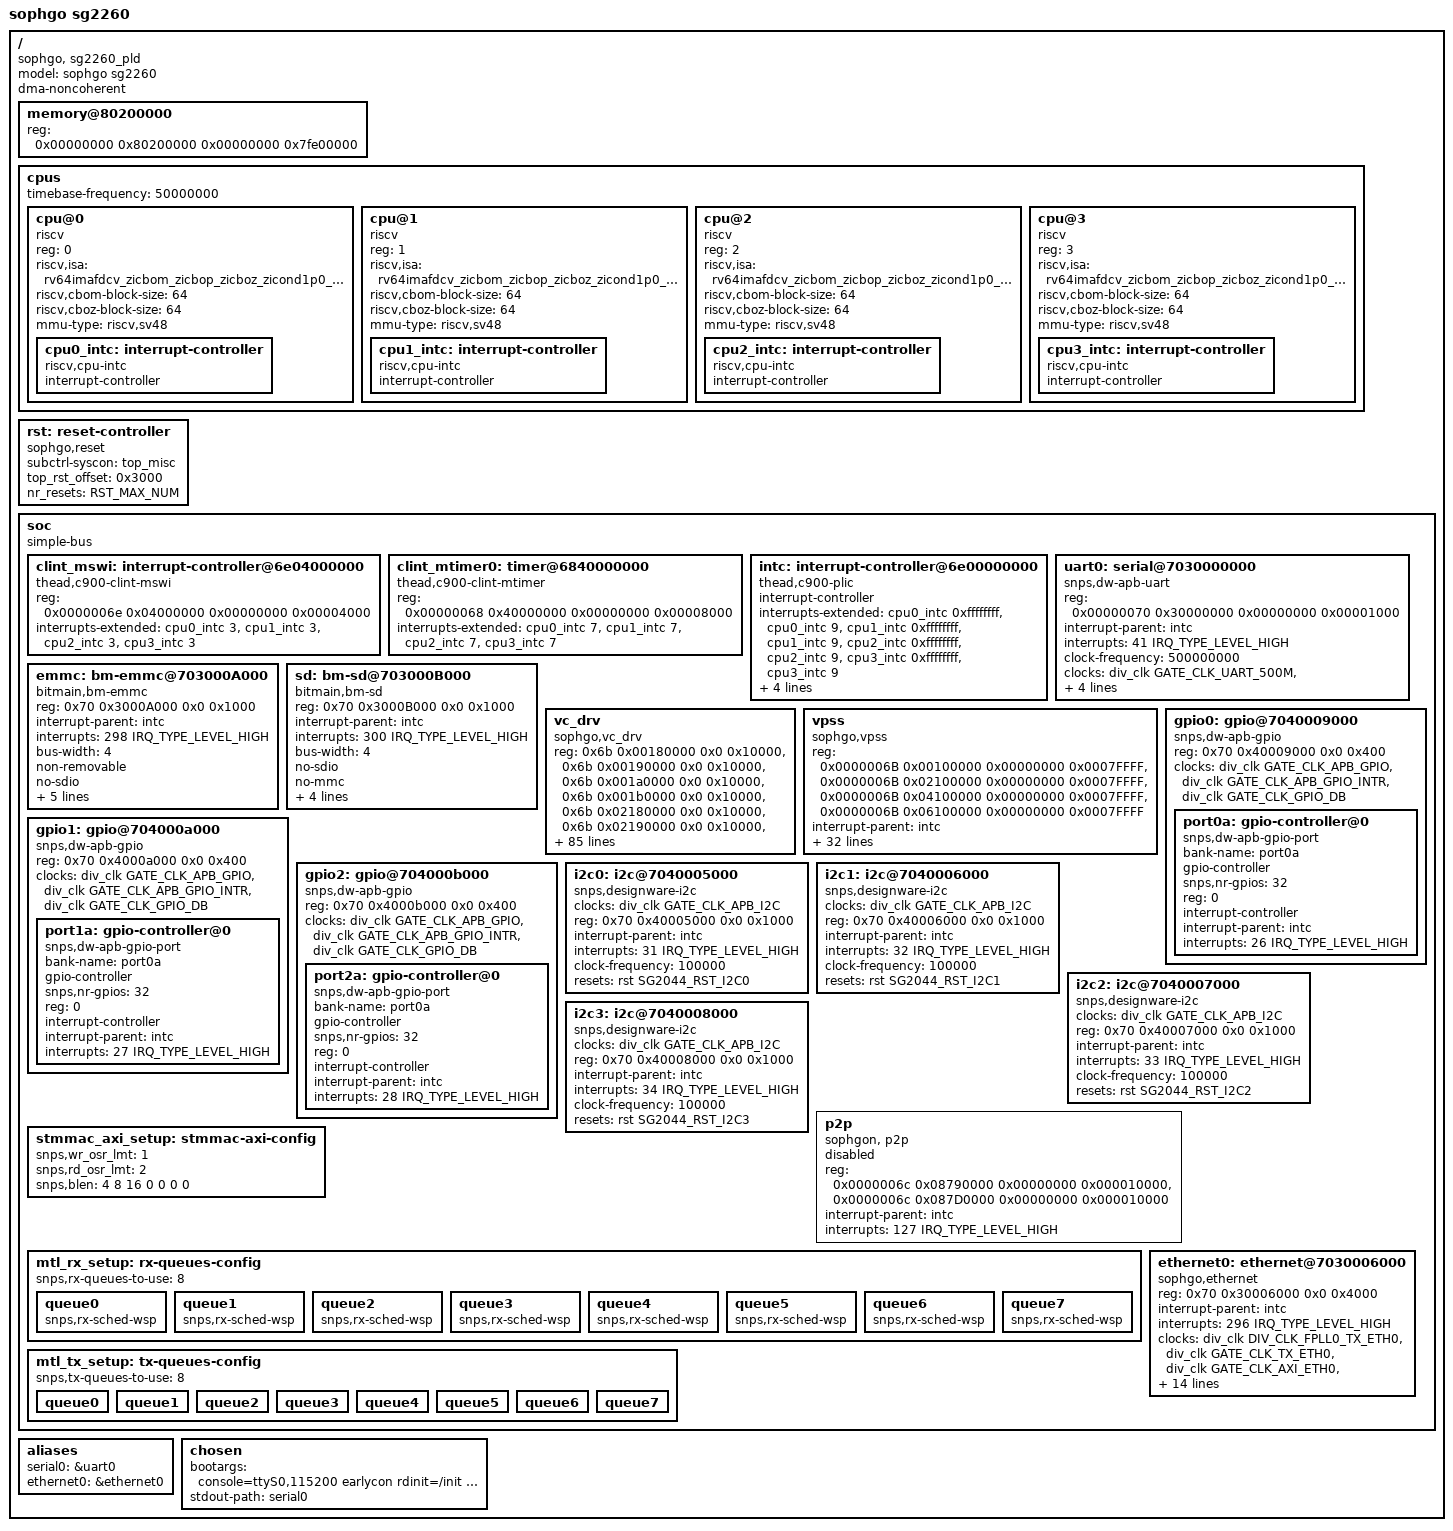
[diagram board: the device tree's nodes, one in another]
// SPDX-License-Identifier: (GPL-2.0 OR MIT)
/*
 * Copyright (C) 2022 Sophgo Technology Inc. All rights reserved.
 */

/dts-v1/;
#include <dt-bindings/interrupt-controller/irq.h>
#include <dt-bindings/reset/sophgo,sg2044-reset.h>
#include <dt-bindings/clock/sophgo,sg2044-clock.h>
#include "sg2044-clock.dtsi"
#include "sg2044-pinctrl.dtsi"

/ {
	model = "sophgo sg2260";
	compatible = "sophgo, sg2260_pld";
	#address-cells = <2>;
	#size-cells = <2>;
	dma-noncoherent;

	memory@80200000 {
		device_type = "memory";
		reg = <0x00000000 0x80200000 0x00000000 0x7fe00000>;
	};

	cpus {
		#address-cells = <1>;
		#size-cells = <0>;
		timebase-frequency = <50000000>;
		cpu@0 {
			device_type = "cpu";
			reg = <0>;
			status = "okay";
			compatible = "riscv";
			riscv,isa = "rv64imafdcv_zicbom_zicbop_zicboz_zicond1p0_zihintntl0p2_zihintpause_zawrs_zfa0p1_zfbfmin0p8_zfh_zca_zcb_zcd_zba_zbb_zbc_zbs_zvfbfmin0p8_zvfbfwma0p8_zvfh0p1_sscofpmf_sstc_svinval_svnapot_svpbmt";
			riscv,cbom-block-size = <64>;
			riscv,cboz-block-size = <64>;
			mmu-type = "riscv,sv48";
			cpu0_intc: interrupt-controller {
				#interrupt-cells = <1>;
				compatible = "riscv,cpu-intc";
				interrupt-controller;
			};
		};
		cpu@1 {
			device_type = "cpu";
			reg = <1>;
			status = "okay";
			compatible = "riscv";
			riscv,isa = "rv64imafdcv_zicbom_zicbop_zicboz_zicond1p0_zihintntl0p2_zihintpause_zawrs_zfa0p1_zfbfmin0p8_zfh_zca_zcb_zcd_zba_zbb_zbc_zbs_zvfbfmin0p8_zvfbfwma0p8_zvfh0p1_sscofpmf_sstc_svinval_svnapot_svpbmt";
			riscv,cbom-block-size = <64>;
			riscv,cboz-block-size = <64>;
			mmu-type = "riscv,sv48";
			cpu1_intc: interrupt-controller {
				#interrupt-cells = <1>;
				compatible = "riscv,cpu-intc";
				interrupt-controller;
			};
		};
		cpu@2 {
			device_type = "cpu";
			reg = <2>;
			status = "okay";
			compatible = "riscv";
			riscv,isa = "rv64imafdcv_zicbom_zicbop_zicboz_zicond1p0_zihintntl0p2_zihintpause_zawrs_zfa0p1_zfbfmin0p8_zfh_zca_zcb_zcd_zba_zbb_zbc_zbs_zvfbfmin0p8_zvfbfwma0p8_zvfh0p1_sscofpmf_sstc_svinval_svnapot_svpbmt";
			riscv,cbom-block-size = <64>;
			riscv,cboz-block-size = <64>;
			mmu-type = "riscv,sv48";
			cpu2_intc: interrupt-controller {
				#interrupt-cells = <1>;
				compatible = "riscv,cpu-intc";
				interrupt-controller;
			};
		};
		cpu@3 {
			device_type = "cpu";
			reg = <3>;
			status = "okay";
			compatible = "riscv";
			riscv,isa = "rv64imafdcv_zicbom_zicbop_zicboz_zicond1p0_zihintntl0p2_zihintpause_zawrs_zfa0p1_zfbfmin0p8_zfh_zca_zcb_zcd_zba_zbb_zbc_zbs_zvfbfmin0p8_zvfbfwma0p8_zvfh0p1_sscofpmf_sstc_svinval_svnapot_svpbmt";
			riscv,cbom-block-size = <64>;
			riscv,cboz-block-size = <64>;
			mmu-type = "riscv,sv48";
			cpu3_intc: interrupt-controller {
				#interrupt-cells = <1>;
				compatible = "riscv,cpu-intc";
				interrupt-controller;
			};
		};
	};

	rst: reset-controller {
		#reset-cells = <1>;
		compatible = "sophgo,reset";
		subctrl-syscon = <&top_misc>;
		top_rst_offset = <0x3000>;
		nr_resets = <RST_MAX_NUM>;
	};

	soc {
		#address-cells = <2>;
		#size-cells = <2>;
		compatible = "simple-bus";
		ranges;

		clint_mswi: interrupt-controller@6e04000000 {
			compatible = "thead,c900-clint-mswi";
			reg = <0x0000006e 0x04000000 0x00000000 0x00004000>;
			interrupts-extended = <
				&cpu0_intc 3
				&cpu1_intc 3
				&cpu2_intc 3
				&cpu3_intc 3
				>;
		};

		clint_mtimer0: timer@6840000000 {
			compatible = "thead,c900-clint-mtimer";
			reg = <0x00000068 0x40000000 0x00000000 0x00008000>;
			interrupts-extended = <
				&cpu0_intc 7
				&cpu1_intc 7
				&cpu2_intc 7
				&cpu3_intc 7
				>;
		};

		//4cores PLIC2
		intc: interrupt-controller@6e00000000 {
			compatible = "thead,c900-plic";
			#address-cells = <0>;
			#interrupt-cells = <2>;
			interrupt-controller;
			interrupts-extended = <
				&cpu0_intc  0xffffffff &cpu0_intc  9
				&cpu1_intc  0xffffffff &cpu1_intc  9
				&cpu2_intc  0xffffffff &cpu2_intc  9
				&cpu3_intc  0xffffffff &cpu3_intc  9
				>;
			reg = <0x0000006e 0x00000000 0x00000000 0x10000000>;
			reg-names = "control";
			riscv,max-priority = <7>;
			riscv,ndev = <415>;
		};

		uart0: serial@7030000000 {
			compatible = "snps,dw-apb-uart";
			reg = <0x00000070 0x30000000 0x00000000 0x00001000>;
			interrupt-parent = <&intc>;
			interrupts = <41 IRQ_TYPE_LEVEL_HIGH>;
			clock-frequency = <500000000>;
			clocks = <&div_clk GATE_CLK_UART_500M>,
					 <&div_clk GATE_CLK_APB_UART>;
			clock-names = "baudclk", "apb_pclk";
			current-speed = <115200>;
			reg-shift = <2>;
			reg-io-width = <4>;
		};

		emmc: bm-emmc@703000A000 {
			compatible = "bitmain,bm-emmc";
			reg = <0x70 0x3000A000 0x0 0x1000>;
			reg-names = "core_mem";
			interrupt-parent = <&intc>;
			interrupts = <298 IRQ_TYPE_LEVEL_HIGH>;
			bus-width = <4>;
			non-removable;
			no-sdio;
			no-sd;
			resets = <&rst SG2044_RST_EMMC>;
			reset-names = "emmc";
			clocks =
				<&div_clk GATE_CLK_EMMC>,
				<&div_clk GATE_CLK_AXI_EMMC>,
				<&div_clk GATE_CLK_100K_EMMC>;
			clock-names =
				"clk_gate_emmc",
				"clk_gate_axi_emmc",
				"clk_gate_100k_emmc";
		};

		sd: bm-sd@703000B000 {
			compatible = "bitmain,bm-sd";
			reg = <0x70 0x3000B000 0x0 0x1000>;
			reg-names = "core_mem";
			interrupt-parent = <&intc>;
			interrupts = <300 IRQ_TYPE_LEVEL_HIGH>;
			bus-width = <4>;
			no-sdio;
			no-mmc;
			resets = <&rst SG2044_RST_SD>;
			reset-names = "sdio";
			clocks =
				<&div_clk GATE_CLK_SD>,
				<&div_clk GATE_CLK_AXI_SD>,
				<&div_clk GATE_CLK_100K_SD>;
			clock-names =
				"clk_gate_sd",
				"clk_gate_axi_sd",
				"clk_gate_100k_sd";
		};

		// video & jpeg
		vc_drv {
            #interrupt-cells = <1>;
            compatible = "sophgo,vc_drv";
            reg = <0x6b 0x00180000 0x0 0x10000>, <0x6b 0x00190000 0x0 0x10000>,
                <0x6b 0x001a0000 0x0 0x10000>, <0x6b 0x001b0000 0x0 0x10000>,
                <0x6b 0x02180000 0x0 0x10000>, <0x6b 0x02190000 0x0 0x10000>,
                <0x6b 0x021a0000 0x0 0x10000>, <0x6b 0x021b0000 0x0 0x10000>,
                <0x6b 0x04180000 0x0 0x10000>, <0x6b 0x04190000 0x0 0x10000>,
                <0x6b 0x041a0000 0x0 0x10000>, <0x6b 0x041b0000 0x0 0x10000>,
                <0x6b 0x06180000 0x0 0x10000>, <0x6b 0x06190000 0x0 0x10000>,
                <0x6b 0x061a0000 0x0 0x10000>, <0x6b 0x061b0000 0x0 0x10000>,
                <0x00 0x00010000 0x0 0x10000>, <0x00 0x00020000 0x0 0x10000>,
                <0x00 0x02010000 0x0 0x10000>, <0x00 0x02020000 0x0 0x10000>,
                <0x00 0x04010000 0x0 0x10000>, <0x00 0x04020000 0x0 0x10000>,
                <0x00 0x06010000 0x0 0x10000>, <0x00 0x06020000 0x0 0x10000>,
                <0x6b 0x00040000 0x0 0x10000>, <0x6b 0x00042000 0x0 0x10000>,
                <0x6b 0x02040000 0x0 0x10000>, <0x6b 0x02042000 0x0 0x10000>,
                <0x6b 0x04040000 0x0 0x10000>, <0x6b 0x04042000 0x0 0x10000>,
                <0x6b 0x06040000 0x0 0x10000>, <0x6b 0x06042000 0x0 0x10000>;

            clocks = <&div_clk GATE_CLK_SRC0>,
                <&div_clk GATE_CLK_SRC1>;
            clock-names = "vc_clk_src0", "vc_intr_src1";

            interrupt-parent = <&intc>;
            interrupts =<161 IRQ_TYPE_LEVEL_HIGH>, <162 IRQ_TYPE_LEVEL_HIGH>,
                    <167 IRQ_TYPE_LEVEL_HIGH>, <168 IRQ_TYPE_LEVEL_HIGH>,
                    <201 IRQ_TYPE_LEVEL_HIGH>, <202 IRQ_TYPE_LEVEL_HIGH>,
                    <207 IRQ_TYPE_LEVEL_HIGH>, <208 IRQ_TYPE_LEVEL_HIGH>,
                    <241 IRQ_TYPE_LEVEL_HIGH>, <242 IRQ_TYPE_LEVEL_HIGH>,
                    <247 IRQ_TYPE_LEVEL_HIGH>, <248 IRQ_TYPE_LEVEL_HIGH>,
                    <281 IRQ_TYPE_LEVEL_HIGH>, <282 IRQ_TYPE_LEVEL_HIGH>,
                    <287 IRQ_TYPE_LEVEL_HIGH>, <288 IRQ_TYPE_LEVEL_HIGH>,
                    <136 IRQ_TYPE_LEVEL_HIGH>, <140 IRQ_TYPE_LEVEL_HIGH>,
                    <176 IRQ_TYPE_LEVEL_HIGH>, <180 IRQ_TYPE_LEVEL_HIGH>,
                    <216 IRQ_TYPE_LEVEL_HIGH>, <220 IRQ_TYPE_LEVEL_HIGH>,
                    <256 IRQ_TYPE_LEVEL_HIGH>, <260 IRQ_TYPE_LEVEL_HIGH>,
                    <137 IRQ_TYPE_LEVEL_HIGH>, <141 IRQ_TYPE_LEVEL_HIGH>,
                    <177 IRQ_TYPE_LEVEL_HIGH>, <181 IRQ_TYPE_LEVEL_HIGH>,
                    <217 IRQ_TYPE_LEVEL_HIGH>, <221 IRQ_TYPE_LEVEL_HIGH>,
                    <257 IRQ_TYPE_LEVEL_HIGH>, <261 IRQ_TYPE_LEVEL_HIGH>,
                    <138 IRQ_TYPE_LEVEL_HIGH>, <142 IRQ_TYPE_LEVEL_HIGH>,
                    <178 IRQ_TYPE_LEVEL_HIGH>, <182 IRQ_TYPE_LEVEL_HIGH>,
                    <218 IRQ_TYPE_LEVEL_HIGH>, <222 IRQ_TYPE_LEVEL_HIGH>,
                    <258 IRQ_TYPE_LEVEL_HIGH>, <262 IRQ_TYPE_LEVEL_HIGH>,
                    <139 IRQ_TYPE_LEVEL_HIGH>, <143 IRQ_TYPE_LEVEL_HIGH>,
                    <179 IRQ_TYPE_LEVEL_HIGH>, <183 IRQ_TYPE_LEVEL_HIGH>,
                    <219 IRQ_TYPE_LEVEL_HIGH>, <223 IRQ_TYPE_LEVEL_HIGH>,
                    <259 IRQ_TYPE_LEVEL_HIGH>, <263 IRQ_TYPE_LEVEL_HIGH>,
                    <148 IRQ_TYPE_LEVEL_HIGH>, <149 IRQ_TYPE_LEVEL_HIGH>,
                    <188 IRQ_TYPE_LEVEL_HIGH>, <189 IRQ_TYPE_LEVEL_HIGH>,
                    <228 IRQ_TYPE_LEVEL_HIGH>, <229 IRQ_TYPE_LEVEL_HIGH>,
                    <267 IRQ_TYPE_LEVEL_HIGH>, <268 IRQ_TYPE_LEVEL_HIGH>;
		};

		vpss {
            #interrupt-cells = <1>;
            compatible = "sophgo,vpss";
            reg = <0x0000006B 0x00100000 0x00000000 0x0007FFFF>,
                <0x0000006B 0x02100000 0x00000000 0x0007FFFF>,
                <0x0000006B 0x04100000 0x00000000 0x0007FFFF>,
                <0x0000006B 0x06100000 0x00000000 0x0007FFFF>;

            interrupt-parent = <&intc>;
            interrupts = <157 IRQ_TYPE_LEVEL_HIGH>, <158 IRQ_TYPE_LEVEL_HIGH>,
                    <159 IRQ_TYPE_LEVEL_HIGH>, <160 IRQ_TYPE_LEVEL_HIGH>,
                    <163 IRQ_TYPE_LEVEL_HIGH>, <164 IRQ_TYPE_LEVEL_HIGH>,
                    <165 IRQ_TYPE_LEVEL_HIGH>, <166 IRQ_TYPE_LEVEL_HIGH>,
                    <197 IRQ_TYPE_LEVEL_HIGH>, <198 IRQ_TYPE_LEVEL_HIGH>,
                    <199 IRQ_TYPE_LEVEL_HIGH>, <200 IRQ_TYPE_LEVEL_HIGH>,
                    <203 IRQ_TYPE_LEVEL_HIGH>, <204 IRQ_TYPE_LEVEL_HIGH>,
                    <205 IRQ_TYPE_LEVEL_HIGH>, <206 IRQ_TYPE_LEVEL_HIGH>,
                    <237 IRQ_TYPE_LEVEL_HIGH>, <238 IRQ_TYPE_LEVEL_HIGH>,
                    <239 IRQ_TYPE_LEVEL_HIGH>, <240 IRQ_TYPE_LEVEL_HIGH>,
                    <243 IRQ_TYPE_LEVEL_HIGH>, <244 IRQ_TYPE_LEVEL_HIGH>,
                    <245 IRQ_TYPE_LEVEL_HIGH>, <246 IRQ_TYPE_LEVEL_HIGH>,
                    <277 IRQ_TYPE_LEVEL_HIGH>, <278 IRQ_TYPE_LEVEL_HIGH>,
                    <279 IRQ_TYPE_LEVEL_HIGH>, <280 IRQ_TYPE_LEVEL_HIGH>,
                    <283 IRQ_TYPE_LEVEL_HIGH>, <284 IRQ_TYPE_LEVEL_HIGH>,
                    <285 IRQ_TYPE_LEVEL_HIGH>, <286 IRQ_TYPE_LEVEL_HIGH>;
		};

		gpio0: gpio@7040009000 {
			compatible = "snps,dw-apb-gpio";
			reg = <0x70 0x40009000 0x0 0x400>;
			#address-cells = <1>;
			#size-cells = <0>;
			clocks = <&div_clk GATE_CLK_APB_GPIO>,
				 <&div_clk GATE_CLK_APB_GPIO_INTR>,
				 <&div_clk GATE_CLK_GPIO_DB>;
			clock-names = "base_clk", "intr_clk", "db_clk";

			port0a: gpio-controller@0 {
				compatible = "snps,dw-apb-gpio-port";
				bank-name = "port0a";
				gpio-controller;
				#gpio-cells = <2>;
				snps,nr-gpios = <32>;
				reg = <0>;
				interrupt-controller;
				#interrupt-cells = <2>;
				interrupt-parent = <&intc>;
				interrupts = <26 IRQ_TYPE_LEVEL_HIGH>;
			};
		};

		gpio1: gpio@704000a000 {
			compatible = "snps,dw-apb-gpio";
			reg = <0x70 0x4000a000 0x0 0x400>;
			#address-cells = <1>;
			#size-cells = <0>;

			clocks = <&div_clk GATE_CLK_APB_GPIO>,
				 <&div_clk GATE_CLK_APB_GPIO_INTR>,
				 <&div_clk GATE_CLK_GPIO_DB>;
			clock-names = "base_clk", "intr_clk", "db_clk";

			port1a: gpio-controller@0 {
				compatible = "snps,dw-apb-gpio-port";
				bank-name = "port0a";
				gpio-controller;
				#gpio-cells = <2>;
				snps,nr-gpios = <32>;
				reg = <0>;
				interrupt-controller;
				#interrupt-cells = <2>;
				interrupt-parent = <&intc>;
				interrupts = <27 IRQ_TYPE_LEVEL_HIGH>;
			};
		};

		gpio2: gpio@704000b000 {
			compatible = "snps,dw-apb-gpio";
			reg = <0x70 0x4000b000 0x0 0x400>;
			#address-cells = <1>;
			#size-cells = <0>;
			clocks = <&div_clk GATE_CLK_APB_GPIO>,
				 <&div_clk GATE_CLK_APB_GPIO_INTR>,
				 <&div_clk GATE_CLK_GPIO_DB>;
			clock-names = "base_clk", "intr_clk", "db_clk";

			port2a: gpio-controller@0 {
				compatible = "snps,dw-apb-gpio-port";
				bank-name = "port0a";
				gpio-controller;
				#gpio-cells = <2>;
				snps,nr-gpios = <32>;
				reg = <0>;
				interrupt-controller;
				#interrupt-cells = <2>;
				interrupt-parent = <&intc>;
				interrupts = <28 IRQ_TYPE_LEVEL_HIGH>;
			};
		};

		i2c0: i2c@7040005000 {
			#address-cells = <1>;
			#size-cells = <0>;
			compatible = "snps,designware-i2c";
			clocks = <&div_clk GATE_CLK_APB_I2C>;
			clock-names = "clk_gate_apb_i2c";
			reg = <0x70 0x40005000 0x0 0x1000>;
			interrupt-parent = <&intc>;
			interrupts = <31 IRQ_TYPE_LEVEL_HIGH>;
			clock-frequency = <100000>;
			resets = <&rst SG2044_RST_I2C0>;
			reset-names = "i2c0";
		};

		i2c1: i2c@7040006000 {
			#address-cells = <1>;
			#size-cells = <0>;
			compatible = "snps,designware-i2c";
			clocks = <&div_clk GATE_CLK_APB_I2C>;
			clock-names = "clk_gate_apb_i2c";
			reg = <0x70 0x40006000 0x0 0x1000>;
			interrupt-parent = <&intc>;
			interrupts = <32 IRQ_TYPE_LEVEL_HIGH>;
			clock-frequency = <100000>;
			resets = <&rst SG2044_RST_I2C1>;
			reset-names = "i2c1";
		};

		i2c2: i2c@7040007000 {
			#address-cells = <1>;
			#size-cells = <0>;
			compatible = "snps,designware-i2c";
			clocks = <&div_clk GATE_CLK_APB_I2C>;
			clock-names = "clk_gate_apb_i2c";
			reg = <0x70 0x40007000 0x0 0x1000>;
			interrupt-parent = <&intc>;
			interrupts = <33 IRQ_TYPE_LEVEL_HIGH>;
			clock-frequency = <100000>;
			resets = <&rst SG2044_RST_I2C2>;
			reset-names = "i2c2";
		};

		i2c3: i2c@7040008000 {
			#address-cells = <1>;
			#size-cells = <0>;
			compatible = "snps,designware-i2c";
			clocks = <&div_clk GATE_CLK_APB_I2C>;
			clock-names = "clk_gate_apb_i2c";
			reg = <0x70 0x40008000 0x0 0x1000>;
			interrupt-parent = <&intc>;
			interrupts = <34 IRQ_TYPE_LEVEL_HIGH>;
			clock-frequency = <100000>;
			resets = <&rst SG2044_RST_I2C3>;
			reset-names = "i2c3";
		};

		p2p:  p2p {
			compatible = "sophgon, p2p";
			reg = <0x0000006c 0x08790000 0x00000000 0x000010000>,
			      <0x0000006c 0x087D0000 0x00000000 0x000010000>;
			reg-names = "cdma_cfg","cxp_top_cfg";
			interrupt-parent = <&intc>;
			interrupts = <127 IRQ_TYPE_LEVEL_HIGH>;
			interrupt-names = "CXP_CDMA0";
			status = "disabled";
		};

		stmmac_axi_setup: stmmac-axi-config {
			snps,wr_osr_lmt = <1>;
			snps,rd_osr_lmt = <2>;
			snps,blen = <4 8 16 0 0 0 0>;
		};

		mtl_rx_setup: rx-queues-config {
			snps,rx-queues-to-use = <8>;
			queue0 {snps,rx-sched-wsp;};
			queue1 {snps,rx-sched-wsp;};
			queue2 {snps,rx-sched-wsp;};
			queue3 {snps,rx-sched-wsp;};
			queue4 {snps,rx-sched-wsp;};
			queue5 {snps,rx-sched-wsp;};
			queue6 {snps,rx-sched-wsp;};
			queue7 {snps,rx-sched-wsp;};
		};

		mtl_tx_setup: tx-queues-config {
			snps,tx-queues-to-use = <8>;
			queue0 {};
			queue1 {};
			queue2 {};
			queue3 {};
			queue4 {};
			queue5 {};
			queue6 {};
			queue7 {};
		};

#if 0
		xlgmac_axi_setup: xlgmac-axi-config {
			snps,wr_osr_lmt = <63>;
			snps,rd_osr_lmt = <3>;
			snps,blen = <4 8 16 32 64 128 256>;
		};

		xlg_mtl_rx_setup: xlg-rx-queues-config {
			snps,rx-queues-to-use = <8>;
			queue0 {snps,rx-sched-wsp;};
			queue1 {snps,rx-sched-wsp;};
			queue2 {snps,rx-sched-wsp;};
			queue3 {snps,rx-sched-wsp;};
			queue4 {snps,rx-sched-wsp;};
			queue5 {snps,rx-sched-wsp;};
			queue6 {snps,rx-sched-wsp;};
			queue7 {snps,rx-sched-wsp;};
		};

		xlg_mtl_tx_setup: xlg-tx-queues-config {
			snps,tx-queues-to-use = <8>;
			queue0 {};
			queue1 {};
			queue2 {};
			queue3 {};
			queue4 {};
			queue5 {};
			queue6 {};
			queue7 {};
		};
#endif
		ethernet0: ethernet@7030006000 {
			compatible = "sophgo,ethernet";
			reg = <0x70 0x30006000 0x0 0x4000>;
			interrupt-names = "macirq";
			interrupt-parent = <&intc>;
			interrupts = <296 IRQ_TYPE_LEVEL_HIGH>;
			clock-names = "clk_tx", "gate_clk_tx", "stmmaceth", "ptp_ref", "gate_clk_ref";
			clocks = <&div_clk DIV_CLK_FPLL0_TX_ETH0>,
				<&div_clk GATE_CLK_TX_ETH0>,
				<&div_clk GATE_CLK_AXI_ETH0>,
				<&div_clk DIV_CLK_FPLL0_PTP_REF_I_ETH0>,
				<&div_clk GATE_CLK_REF_ETH0>;
			/* no hash filter and perfect filter support */
			snps,multicast-filter-bins = <0>;
			snps,perfect-filter-entries = <1>;

			snps,txpbl = <32>;
			snps,rxpbl = <32>;
			snps,aal;
			snps,tso;

			snps,axi-config = <&stmmac_axi_setup>;
			snps,mtl-rx-config = <&mtl_rx_setup>;
			snps,mtl-tx-config = <&mtl_tx_setup>;

			sophgo,gmac;

			phy-mode = "rgmii-id";
			phy-reset-gpios = <&port0a 28 0>;
		};
#if 0
		dwcxlg0: dwcxlg@6c08000000 {
			compatible = "sophgo,ethernet";
			reg = <0x6c 0x08000000 0x0 0x40000>;
			interrupt-parent = <&intc>;
			#if 1
			interrupts = <92 IRQ_TYPE_LEVEL_HIGH 93 IRQ_TYPE_LEVEL_HIGH
						  94 IRQ_TYPE_LEVEL_HIGH 95 IRQ_TYPE_LEVEL_HIGH
						  96 IRQ_TYPE_LEVEL_HIGH 97 IRQ_TYPE_LEVEL_HIGH
						  98 IRQ_TYPE_LEVEL_HIGH 99 IRQ_TYPE_LEVEL_HIGH
						  100 IRQ_TYPE_LEVEL_HIGH
						  109 IRQ_TYPE_LEVEL_HIGH 110 IRQ_TYPE_LEVEL_HIGH
						  111 IRQ_TYPE_LEVEL_HIGH 112 IRQ_TYPE_LEVEL_HIGH
						  113 IRQ_TYPE_LEVEL_HIGH 114 IRQ_TYPE_LEVEL_HIGH
						  115 IRQ_TYPE_LEVEL_HIGH 116 IRQ_TYPE_LEVEL_HIGH>;
			interrupt-names = "macirq", "tx_ch0", "tx_ch1", "tx_ch2", "tx_ch3",
							   "tx_ch4", "tx_ch5", "tx_ch6",
							   "rx_ch0", "rx_ch1", "rx_ch2", "rx_ch3",
							   "rx_ch4", "rx_ch5", "rx_ch6", "rx_ch7";
			snps,multi_msi_en;
			#else
			interrupts = <92 IRQ_TYPE_LEVEL_HIGH>;
			interrupt-names = "macirq";
			#endif
			snps,tso;
			snps,axi-config = <&xlgmac_axi_setup>;
			snps,mtl-rx-config = <&xlg_mtl_rx_setup>;
			snps,mtl-tx-config = <&xlg_mtl_tx_setup>;

			phy-mode = "xlgmii";
			fixed-link {
				speed = <100000>;
				full-duplex;
			};
		};
#endif
	};

	aliases {
		serial0 = &uart0;
		ethernet0 = &ethernet0;
		//dwcxlg0 = &dwcxlg0;

	};

	chosen {
		bootargs = "console=ttyS0,115200 earlycon rdinit=/init root=/dev/ram0 rw initrd=0x8b000000,32M rdmem=0x100000000,2040M maxcpus=4 no5lvl";
		stdout-path = "serial0";
	};
};
